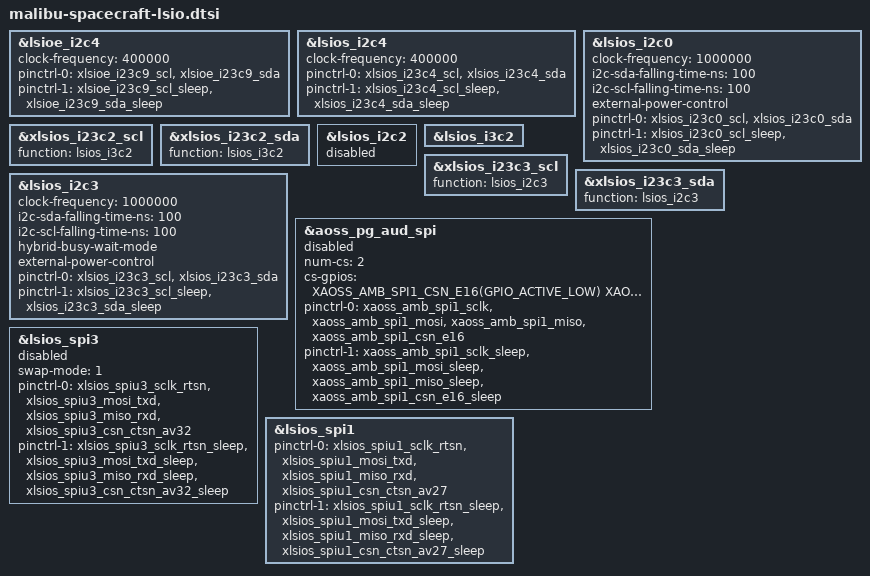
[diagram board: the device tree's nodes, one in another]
// SPDX-License-Identifier: GPL-2.0 OR BSD-3-Clause
/*
 * Board level low speed interfaces configuration
 *
 * Copyright 2025 Google LLC
 */

#include <dt-bindings/gpio/gpio.h>
#include <dt-bindings/gpio/google,mbu.h>
#include <dt-bindings/lpcm/reset_mbu.h>

/*
 * I2C/I3C buses
 * DISP0 PMIC
 */
&lsioe_i2c4 {
	clock-frequency = <400000>;

	pinctrl-0 = <&xlsioe_i23c9_scl>, <&xlsioe_i23c9_sda>;
	pinctrl-1 = <&xlsioe_i23c9_scl_sleep>, <&xlsioe_i23c9_sda_sleep>;

	status = "okay";
};

/*
 * DISP1 PMIC
 */
&lsios_i2c4 {
	clock-frequency = <400000>;

	pinctrl-0 = <&xlsios_i23c4_scl>, <&xlsios_i23c4_sda>;
	pinctrl-1 = <&xlsios_i23c4_scl_sleep>, <&xlsios_i23c4_sda_sleep>;

	status = "okay";
};

/* Camera OUTER FCAM */
&lsios_i2c0 {
	clock-frequency = <1000000>;
	i2c-sda-falling-time-ns = <100>;
	i2c-scl-falling-time-ns = <100>;

	external-power-control;

	pinctrl-0 = <&xlsios_i23c0_scl>, <&xlsios_i23c0_sda>;
	pinctrl-1 = <&xlsios_i23c0_scl_sleep>, <&xlsios_i23c0_sda_sleep>;

	status = "okay";
};

/* Camera RCAM */
&xlsios_i23c2_scl {
	function = "lsios_i3c2";
};

&xlsios_i23c2_sda {
	function = "lsios_i3c2";
};

&lsios_i2c2 {
	status = "disabled";
};

&lsios_i3c2 {
	status = "okay";
};

/* Camera RTCAM (CSIF) */
&xlsios_i23c3_scl {
	function = "lsios_i2c3";
};
&xlsios_i23c3_sda {
	function = "lsios_i2c3";
};
&lsios_i2c3 {
	clock-frequency = <1000000>;
	i2c-sda-falling-time-ns = <100>;
	i2c-scl-falling-time-ns = <100>;

	hybrid-busy-wait-mode;
	external-power-control;

	pinctrl-0 = <&xlsios_i23c3_scl>, <&xlsios_i23c3_sda>;
	pinctrl-1 = <&xlsios_i23c3_scl_sleep>, <&xlsios_i23c3_sda_sleep>;

	status = "okay";
};

/* Two audio amplifiers */
&aoss_pg_aud_spi {
	num-cs = <2>;
	cs-gpios = <XAOSS_AMB_SPI1_CSN_E16(GPIO_ACTIVE_LOW)
			XAOSS_SC_SPI6_SCLK_F5(GPIO_ACTIVE_LOW)>;

	pinctrl-0 = <&xaoss_amb_spi1_sclk>, <&xaoss_amb_spi1_mosi>,
			<&xaoss_amb_spi1_miso>, <&xaoss_amb_spi1_csn_e16>,
			<&xaoss_sc_spi6_sclk_f5>;
	pinctrl-1 = <&xaoss_amb_spi1_sclk_sleep>, <&xaoss_amb_spi1_mosi_sleep>,
			<&xaoss_amb_spi1_miso_sleep>, <&xaoss_amb_spi1_csn_e16_sleep>,
			<&xaoss_sc_spi6_sclk_f5_sleep>;

	status = "disabled";
};

/* GNSS */
&lsios_spi3 {
	swap-mode = <1>;

	pinctrl-0 = <&xlsios_spiu3_sclk_rtsn>, <&xlsios_spiu3_mosi_txd>,
			<&xlsios_spiu3_miso_rxd>, <&xlsios_spiu3_csn_ctsn_av32>;
	pinctrl-1 = <&xlsios_spiu3_sclk_rtsn_sleep>, <&xlsios_spiu3_mosi_txd_sleep>,
			<&xlsios_spiu3_miso_rxd_sleep>, <&xlsios_spiu3_csn_ctsn_av32_sleep>;

	status = "disabled";
};

/* Inner touch */
&aoss_pg_aud_spi {
	pinctrl-0 = <&xaoss_amb_spi1_sclk>, <&xaoss_amb_spi1_mosi>,
		    <&xaoss_amb_spi1_miso>, <&xaoss_amb_spi1_csn_e16>;
	pinctrl-1 = <&xaoss_amb_spi1_sclk_sleep>, <&xaoss_amb_spi1_mosi_sleep>,
		    <&xaoss_amb_spi1_miso_sleep>, <&xaoss_amb_spi1_csn_e16_sleep>;

	status = "disabled";
};

/* LDAF */
&lsios_spi1 {
	pinctrl-0 = <&xlsios_spiu1_sclk_rtsn>, <&xlsios_spiu1_mosi_txd>,
		    <&xlsios_spiu1_miso_rxd>, <&xlsios_spiu1_csn_ctsn_av27>;
	pinctrl-1 = <&xlsios_spiu1_sclk_rtsn_sleep>, <&xlsios_spiu1_mosi_txd_sleep>,
		    <&xlsios_spiu1_miso_rxd_sleep>, <&xlsios_spiu1_csn_ctsn_av27_sleep>;

	status = "okay";
};
